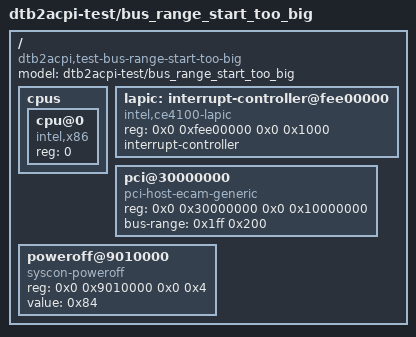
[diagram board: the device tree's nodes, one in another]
/dts-v1/;

/* `bus-range = <0x1ff 0x200>;` — start > 255. The existing
 * `bus_range_too_big.dts` has start ≤ 255 and only end overflows,
 * so the start narrowing arm in `decode_pci_bus_range` was never
 * exercised. Here, start is checked first and fires
 * `ValueOutOfRange { site: PciHost, property: "bus-range" }`.
 */

/ {
	#address-cells = <2>;
	#size-cells = <2>;
	model = "dtb2acpi-test/bus_range_start_too_big";
	compatible = "dtb2acpi,test-bus-range-start-too-big";

	cpus {
		#address-cells = <1>;
		#size-cells = <0>;

		cpu@0 {
			device_type = "cpu";
			reg = <0>;
			compatible = "intel,x86";
		};
	};

		lapic: interrupt-controller@fee00000 {
		compatible = "intel,ce4100-lapic";
		reg = <0x0 0xfee00000 0x0 0x1000>;
		interrupt-controller;
		#interrupt-cells = <2>;
	};

	pci@30000000 {
		compatible = "pci-host-ecam-generic";
		device_type = "pci";
		reg = <0x0 0x30000000 0x0 0x10000000>;
		bus-range = <0x1ff 0x200>;
		#address-cells = <3>;
		#size-cells = <2>;
	};
		poweroff@9010000 {
		compatible = "syscon-poweroff";
		reg = <0x0 0x9010000 0x0 0x4>;
		value = <0x84>;
	};
};
